# Z32F0641 register map
Vendor: Zilog, Inc; File version: 1.0
CPU: CM3 r1p0, little endian, no MPU, no FPU, 3 interrupt priority bits
Registers are 32-bit, read-write, reset 0x0 unless marked. A register's access mark holds for its fields unless they carry their own. Offsets are from the block's base; [hi:lo] are bit positions; {n}, {i} and the like mark numbered series; 'fields as' and 'values as' point back to an identical list.

## MP0 — MOTOR PULSE-WIDTH-MODULATOR
Base 0x40004000
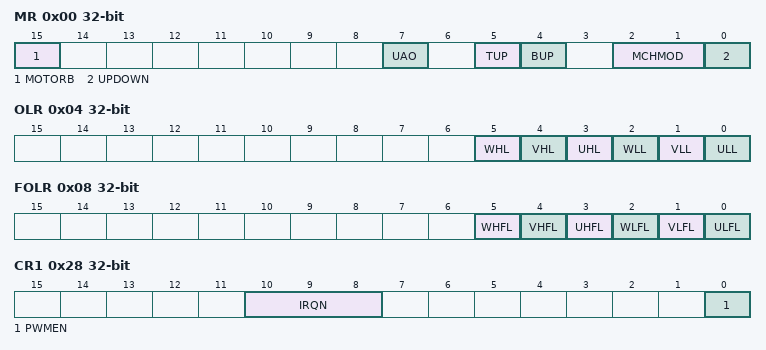
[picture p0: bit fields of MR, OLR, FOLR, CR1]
0x00 MR — MPWM Mode Register
  [15] MOTORB — Normal/Motor mode
  [7] UAO — update mode
  [5] TUP — Period match update mode
  [4] BUP — Bottom match update mode
  [2:1] MCHMOD — Motor Control Mode
  [0] UPDOWN — PWM counter mode
0x04 OLR — MPWM Output Level Register
  [5] WHL — W High Output Level
  [4] VHL — V High Output Level
  [3] UHL — U High Output Level
  [2] WLL — W Low Output Level
  [1] VLL — V Low Output Level
  [0] ULL — U Low Output Level
0x08 FOLR — MPWM Force Output Level Control Register
  [5] WHFL — W High Forced Output Level
  [4] VHFL — V High Forced Output Level
  [3] UHFL — U High Forced Output Level
  [2] WLFL — W Low Forced Output Level
  [1] VLFL — V Low Forced Output Level
  [0] ULFL — U Low Forced Output Level
0x0C PRD — MPWM Period Register
  [15:0] PERIOD — PWM period
0x10 DUH — MPWM Duty UH Register
  [15:0] DUTY — duty of UH output
0x14 DVH — MPWM Duty VH Register
  [15:0] DUTY — duty of VH data
0x18 DWH — MPWM Duty WH Register
  [15:0] DUTY — duty of WH output
0x1C DUL — MPWM Duty UL Register
  [15:0] DUTY — duty of UL output
0x20 DVL — MPWM Duty UL Register
  [15:0] DUTY — duty of VL output
0x24 DWL — MPWM Duty WL Register
  [15:0] DUTY — duty of WL output
0x28 CR1 — MPWM Control Register 1
  [10:8] IRQN — IRQ interval Number
  [0] PWMEN — PWM enable
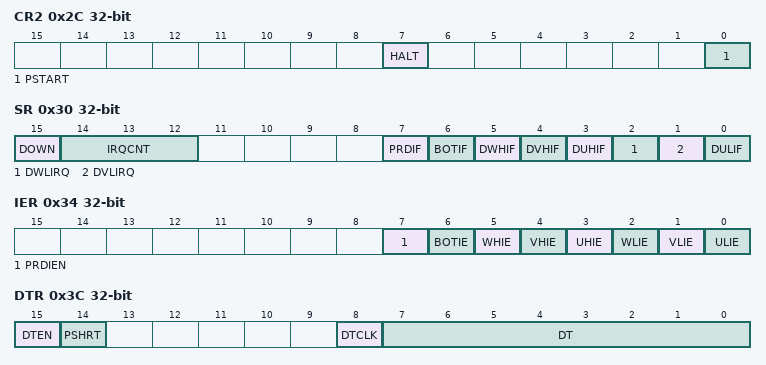
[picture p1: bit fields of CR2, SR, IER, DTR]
0x2C CR2 — MPWM Control Register 2
  [7] HALT — PWM HALT
  [0] PSTART — PWM start
0x30 SR — MPWM Status Register
  [15] DOWN — PWM count up/down
  [14:12] IRQCNT — PWM count number of period match
  [7] PRDIF — PWM period interrupt flag
  [6] BOTIF — PWM bottom interrupt flag
  [5] DWHIF — duty WH interrupt flag
  [4] DVHIF — duty VH interrupt flag
  [3] DUHIF — duty UH interrupt flag
  [2] DWLIRQ — duty WL interrupt flag
  [1] DVLIRQ — duty VL interrupt flag
  [0] DULIF — duty UL interrupt flag
0x34 IER — MPWM Interrupt Enable Register
  [7] PRDIEN — Period interrupt enable
  [6] BOTIE — bottom interrupt enable
  [5] WHIE — duty WH interrupt enable
  [4] VHIE — duty VH interrupt enable
  [3] UHIE — duty UH interrupt enable
  [2] WLIE — duty WL interrupt enable
  [1] VLIE — duty VL interrupt enable
  [0] ULIE — duty UL interrupt enable
0x38 CNT — MPWM Counter Register
  [15:0] CNT — pwm counter value
0x3C DTR — MPWM Dead Time Register
  [15] DTEN — dead time Enable
  [14] PSHRT — Protect Short Condition
  [8] DTCLK — dead time clk select
  [7:0] DT — dead time value
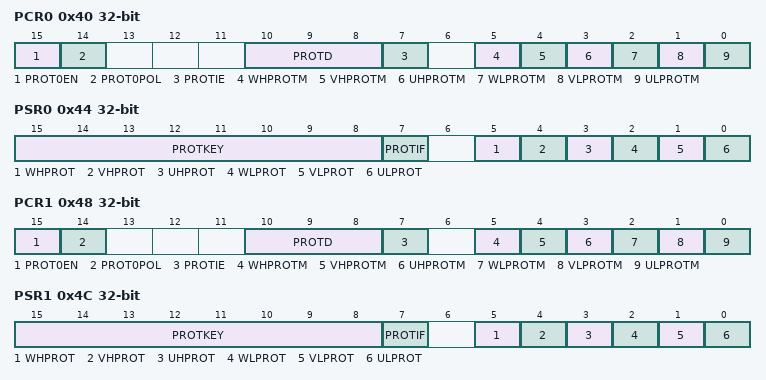
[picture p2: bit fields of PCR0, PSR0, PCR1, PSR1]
0x40 PCR0 — MPWM Protection control Register
  [15] PROT0EN — Protection Input 0 Enable
  [14] PROT0POL — Protection Input 0 Polarity
  [10:8] PROTD — Protection Input Debounce
  [7] PROTIE — Protection Interrup Enable
  [5] WHPROTM — W phase High protection output
  [4] VHPROTM — V phase High protection output
  [3] UHPROTM — U phase High protection output
  [2] WLPROTM — W phase Low protection output
  [1] VLPROTM — V phase Low protection output
  [0] ULPROTM — U phase Low protection output
0x44 PSR0 — MPWM Protection 0 Status Register
  [15:8] PROTKEY — lock safety pattern to set or reset protection
  [7] PROTIF — Protection Interrupt Flag
  [5] WHPROT — W phase High protection status
  [4] VHPROT — V phase High protection status
  [3] UHPROT — U phase High protection status
  [2] WLPROT — W phase Low protection status
  [1] VLPROT — V phase Low protection status
  [0] ULPROT — U phase Low protection status
0x48 PCR1 — MPWM Protection control 1 Register
  fields as PCR0
0x4C PSR1 — MPWM Protection 1 Status Register
  fields as PSR0
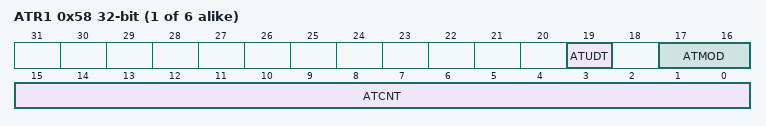
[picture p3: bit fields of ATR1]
{0x54+4i} ATR{i} (i=1..6) — MPWMn ADC Trigger Counter {i} Register
  [19] ATUDT — Trigger register update mode
  [17:16] ATMOD — ADC Trigger mode register
  [15:0] ATCNT — ADC Trigger counter
